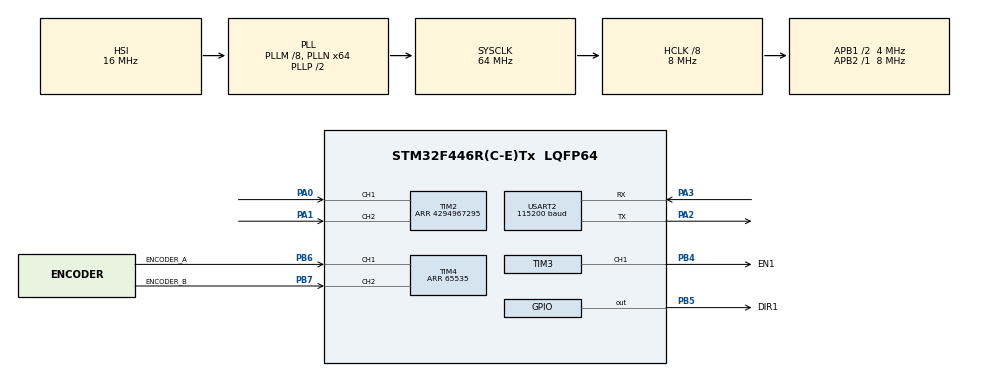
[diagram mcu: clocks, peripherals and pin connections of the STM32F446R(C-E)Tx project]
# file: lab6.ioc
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Mcu.Family=STM32F4
Mcu.Name=STM32F446R(C-E)Tx
Mcu.Package=LQFP64
NVIC.PriorityGroup=NVIC_PRIORITYGROUP_4
NVIC.TIM3_IRQn=true\:0\:0\:false\:false\:true\:true\:true\:true
NVIC.TIM7_IRQn=true\:0\:0\:false\:false\:true\:true\:true\:true
PA0-WKUP.Signal=S_TIM2_CH1_ETR
PA1.Signal=S_TIM2_CH2
PA2.Mode=Asynchronous
PA2.Signal=USART2_TX
PA3.Mode=Asynchronous
PA3.Signal=USART2_RX
PB4.GPIO_Label=EN1
PB4.Signal=S_TIM3_CH1
PB5.GPIO_Label=DIR1
PB5.Signal=GPIO_Output
PB6.GPIO_Label=ENCODER_A
PB6.Signal=S_TIM4_CH1
PB7.GPIO_Label=ENCODER_B
PB7.Signal=S_TIM4_CH2
ProjectManager.HeapSize=0x200
ProjectManager.StackSize=0x400
ProjectManager.TargetToolchain=STM32CubeIDE
RCC.AHBCLKDivider=RCC_SYSCLK_DIV8
RCC.AHBFreq_Value=8000000
RCC.APB1CLKDivider=RCC_HCLK_DIV2
RCC.APB1Freq_Value=4000000
RCC.APB1TimFreq_Value=8000000
RCC.APB2Freq_Value=8000000
RCC.APB2TimFreq_Value=8000000
RCC.CortexFreq_Value=8000000
RCC.HCLKFreq_Value=8000000
RCC.PLLM=8
RCC.PLLN=64
RCC.SYSCLKFreq_VALUE=64000000
RCC.SYSCLKSource=RCC_SYSCLKSOURCE_PLLCLK
RCC.USBFreq_Value=64000000
RCC.VCOOutputFreq_Value=128000000
SH.S_TIM2_CH1_ETR.0=TIM2_CH1,Encoder_Interface
SH.S_TIM2_CH2.0=TIM2_CH2,Encoder_Interface
SH.S_TIM3_CH1.0=TIM3_CH1,PWM Generation1 CH1
SH.S_TIM4_CH1.0=TIM4_CH1,Encoder_Interface
SH.S_TIM4_CH2.0=TIM4_CH2,Encoder_Interface
TIM2.ClockDivision=TIM_CLOCKDIVISION_DIV2
TIM2.Period=4294967295
TIM3.Channel-PWM\ Generation1\ CH1=TIM_CHANNEL_1
TIM3.Period=7
TIM3.Prescaler=499
TIM4.ClockDivision=TIM_CLOCKDIVISION_DIV2
TIM4.Period=65535
TIM7.Period=79
TIM7.Prescaler=499
USART2.BaudRate=115200
USART2.VirtualMode=VM_ASYNC
VP_TIM3_VS_ClockSourceINT.Mode=Internal
VP_TIM7_VS_ClockSourceINT.Mode=Enable_Timer
board=custom

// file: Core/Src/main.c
/* USER CODE BEGIN Header */
/**
  ******************************************************************************
  * @file           : main.c
  * @brief          : Main program body
  ******************************************************************************
  * @attention
  *
  * Copyright (c) 2024 STMicroelectronics.
  * All rights reserved.
  *
  * This software is licensed under terms that can be found in the LICENSE file
  * in the root directory of this software component.
  * If no LICENSE file comes with this software, it is provided AS-IS.
  *
  ******************************************************************************
  */
/* USER CODE END Header */
#include "main.h"

 TIM_HandleTypeDef htim2;
TIM_HandleTypeDef htim3;
TIM_HandleTypeDef htim4;
TIM_HandleTypeDef htim7;

UART_HandleTypeDef huart2;

void SystemClock_Config(void);
static void MX_GPIO_Init(void);
static void MX_TIM3_Init(void);
static void MX_USART2_UART_Init(void);
static void MX_TIM4_Init(void);
static void MX_TIM2_Init(void);
static void MX_TIM7_Init(void);

int main(void)
{

  /* MCU Configuration--------------------------------------------------------*/

  /* Reset of all peripherals, Initializes the Flash interface and the Systick. */
  HAL_Init();

  /* Configure the system clock */
  SystemClock_Config();

  /* Initialize all configured peripherals */
  MX_GPIO_Init();
  MX_TIM3_Init();
  MX_USART2_UART_Init();
  MX_TIM4_Init();
  MX_TIM2_Init();
  MX_TIM7_Init();

  /* Infinite loop */
  /* USER CODE BEGIN WHILE */
  HAL_TIM_Base_Start_IT(&htim7);
  HAL_TIM_PWM_Start_IT(&htim3, TIM_CHANNEL_1);
  HAL_TIM_Encoder_Start(&htim4, TIM_CHANNEL_ALL);
  HAL_TIM_Encoder_Start(&htim2, TIM_CHANNEL_ALL);
  while (1)
  {
    /* USER CODE END WHILE */

  }
}

void SystemClock_Config(void)
{
  RCC_OscInitTypeDef RCC_OscInitStruct = {0};
  RCC_ClkInitTypeDef RCC_ClkInitStruct = {0};

  /** Configure the main internal regulator output voltage
  */
  __HAL_RCC_PWR_CLK_ENABLE();
  __HAL_PWR_VOLTAGESCALING_CONFIG(PWR_REGULATOR_VOLTAGE_SCALE3);

  /** Initializes the RCC Oscillators according to the specified parameters
  * in the RCC_OscInitTypeDef structure.
  */
  RCC_OscInitStruct.OscillatorType = RCC_OSCILLATORTYPE_HSI;
  RCC_OscInitStruct.HSIState = RCC_HSI_ON;
  RCC_OscInitStruct.HSICalibrationValue = RCC_HSICALIBRATION_DEFAULT;
  RCC_OscInitStruct.PLL.PLLState = RCC_PLL_ON;
  RCC_OscInitStruct.PLL.PLLSource = RCC_PLLSOURCE_HSI;
  RCC_OscInitStruct.PLL.PLLM = 8;
  RCC_OscInitStruct.PLL.PLLN = 64;
  RCC_OscInitStruct.PLL.PLLP = RCC_PLLP_DIV2;
  RCC_OscInitStruct.PLL.PLLQ = 2;
  RCC_OscInitStruct.PLL.PLLR = 2;
  if (HAL_RCC_OscConfig(&RCC_OscInitStruct) != HAL_OK)
  {
    Error_Handler();
  }

  /** Initializes the CPU, AHB and APB buses clocks
  */
  RCC_ClkInitStruct.ClockType = RCC_CLOCKTYPE_HCLK|RCC_CLOCKTYPE_SYSCLK
                              |RCC_CLOCKTYPE_PCLK1|RCC_CLOCKTYPE_PCLK2;
  RCC_ClkInitStruct.SYSCLKSource = RCC_SYSCLKSOURCE_PLLCLK;
  RCC_ClkInitStruct.AHBCLKDivider = RCC_SYSCLK_DIV8;
  RCC_ClkInitStruct.APB1CLKDivider = RCC_HCLK_DIV2;
  RCC_ClkInitStruct.APB2CLKDivider = RCC_HCLK_DIV1;

  if (HAL_RCC_ClockConfig(&RCC_ClkInitStruct, FLASH_LATENCY_0) != HAL_OK)
  {
    Error_Handler();
  }
}

static void MX_TIM2_Init(void)
{

  TIM_Encoder_InitTypeDef sConfig = {0};
  TIM_MasterConfigTypeDef sMasterConfig = {0};

  htim2.Instance = TIM2;
  htim2.Init.Prescaler = 0;
  htim2.Init.CounterMode = TIM_COUNTERMODE_UP;
  htim2.Init.Period = 4294967295;
  htim2.Init.ClockDivision = TIM_CLOCKDIVISION_DIV2;
  htim2.Init.AutoReloadPreload = TIM_AUTORELOAD_PRELOAD_DISABLE;
  sConfig.EncoderMode = TIM_ENCODERMODE_TI1;
  sConfig.IC1Polarity = TIM_ICPOLARITY_RISING;
  sConfig.IC1Selection = TIM_ICSELECTION_DIRECTTI;
  sConfig.IC1Prescaler = TIM_ICPSC_DIV1;
  sConfig.IC1Filter = 0;
  sConfig.IC2Polarity = TIM_ICPOLARITY_RISING;
  sConfig.IC2Selection = TIM_ICSELECTION_DIRECTTI;
  sConfig.IC2Prescaler = TIM_ICPSC_DIV1;
  sConfig.IC2Filter = 0;
  if (HAL_TIM_Encoder_Init(&htim2, &sConfig) != HAL_OK)
  {
    Error_Handler();
  }
  sMasterConfig.MasterOutputTrigger = TIM_TRGO_RESET;
  sMasterConfig.MasterSlaveMode = TIM_MASTERSLAVEMODE_DISABLE;
  if (HAL_TIMEx_MasterConfigSynchronization(&htim2, &sMasterConfig) != HAL_OK)
  {
    Error_Handler();
  }

}

static void MX_TIM3_Init(void)
{

  TIM_ClockConfigTypeDef sClockSourceConfig = {0};
  TIM_MasterConfigTypeDef sMasterConfig = {0};
  TIM_OC_InitTypeDef sConfigOC = {0};

  htim3.Instance = TIM3;
  htim3.Init.Prescaler = 499;
  htim3.Init.CounterMode = TIM_COUNTERMODE_UP;
  htim3.Init.Period = 7;
  htim3.Init.ClockDivision = TIM_CLOCKDIVISION_DIV1;
  htim3.Init.AutoReloadPreload = TIM_AUTORELOAD_PRELOAD_DISABLE;
  if (HAL_TIM_Base_Init(&htim3) != HAL_OK)
  {
    Error_Handler();
  }
  sClockSourceConfig.ClockSource = TIM_CLOCKSOURCE_INTERNAL;
  if (HAL_TIM_ConfigClockSource(&htim3, &sClockSourceConfig) != HAL_OK)
  {
    Error_Handler();
  }
  if (HAL_TIM_PWM_Init(&htim3) != HAL_OK)
  {
    Error_Handler();
  }
  sMasterConfig.MasterOutputTrigger = TIM_TRGO_RESET;
  sMasterConfig.MasterSlaveMode = TIM_MASTERSLAVEMODE_DISABLE;
  if (HAL_TIMEx_MasterConfigSynchronization(&htim3, &sMasterConfig) != HAL_OK)
  {
    Error_Handler();
  }
  sConfigOC.OCMode = TIM_OCMODE_PWM1;
  sConfigOC.Pulse = 0;
  sConfigOC.OCPolarity = TIM_OCPOLARITY_HIGH;
  sConfigOC.OCFastMode = TIM_OCFAST_DISABLE;
  if (HAL_TIM_PWM_ConfigChannel(&htim3, &sConfigOC, TIM_CHANNEL_1) != HAL_OK)
  {
    Error_Handler();
  }
  HAL_TIM_MspPostInit(&htim3);

}

static void MX_TIM4_Init(void)
{

  TIM_Encoder_InitTypeDef sConfig = {0};
  TIM_MasterConfigTypeDef sMasterConfig = {0};

  htim4.Instance = TIM4;
  htim4.Init.Prescaler = 0;
  htim4.Init.CounterMode = TIM_COUNTERMODE_UP;
  htim4.Init.Period = 65535;
  htim4.Init.ClockDivision = TIM_CLOCKDIVISION_DIV2;
  htim4.Init.AutoReloadPreload = TIM_AUTORELOAD_PRELOAD_DISABLE;
  sConfig.EncoderMode = TIM_ENCODERMODE_TI1;
  sConfig.IC1Polarity = TIM_ICPOLARITY_RISING;
  sConfig.IC1Selection = TIM_ICSELECTION_DIRECTTI;
  sConfig.IC1Prescaler = TIM_ICPSC_DIV1;
  sConfig.IC1Filter = 0;
  sConfig.IC2Polarity = TIM_ICPOLARITY_RISING;
  sConfig.IC2Selection = TIM_ICSELECTION_DIRECTTI;
  sConfig.IC2Prescaler = TIM_ICPSC_DIV1;
  sConfig.IC2Filter = 0;
  if (HAL_TIM_Encoder_Init(&htim4, &sConfig) != HAL_OK)
  {
    Error_Handler();
  }
  sMasterConfig.MasterOutputTrigger = TIM_TRGO_RESET;
  sMasterConfig.MasterSlaveMode = TIM_MASTERSLAVEMODE_DISABLE;
  if (HAL_TIMEx_MasterConfigSynchronization(&htim4, &sMasterConfig) != HAL_OK)
  {
    Error_Handler();
  }

}

static void MX_TIM7_Init(void)
{

  TIM_MasterConfigTypeDef sMasterConfig = {0};

  htim7.Instance = TIM7;
  htim7.Init.Prescaler = 499;
  htim7.Init.CounterMode = TIM_COUNTERMODE_UP;
  htim7.Init.Period = 79;
  htim7.Init.AutoReloadPreload = TIM_AUTORELOAD_PRELOAD_DISABLE;
  if (HAL_TIM_Base_Init(&htim7) != HAL_OK)
  {
    Error_Handler();
  }
  sMasterConfig.MasterOutputTrigger = TIM_TRGO_RESET;
  sMasterConfig.MasterSlaveMode = TIM_MASTERSLAVEMODE_DISABLE;
  if (HAL_TIMEx_MasterConfigSynchronization(&htim7, &sMasterConfig) != HAL_OK)
  {
    Error_Handler();
  }

}

static void MX_USART2_UART_Init(void)
{

  huart2.Instance = USART2;
  huart2.Init.BaudRate = 115200;
  huart2.Init.WordLength = UART_WORDLENGTH_8B;
  huart2.Init.StopBits = UART_STOPBITS_1;
  huart2.Init.Parity = UART_PARITY_NONE;
  huart2.Init.Mode = UART_MODE_TX_RX;
  huart2.Init.HwFlowCtl = UART_HWCONTROL_NONE;
  huart2.Init.OverSampling = UART_OVERSAMPLING_16;
  if (HAL_UART_Init(&huart2) != HAL_OK)
  {
    Error_Handler();
  }

}

static void MX_GPIO_Init(void)
{
  GPIO_InitTypeDef GPIO_InitStruct = {0};

  /* GPIO Ports Clock Enable */
  __HAL_RCC_GPIOA_CLK_ENABLE();
  __HAL_RCC_GPIOB_CLK_ENABLE();

  /*Configure GPIO pin Output Level */
  HAL_GPIO_WritePin(DIR1_GPIO_Port, DIR1_Pin, GPIO_PIN_RESET);

  /*Configure GPIO pin : DIR1_Pin */
  GPIO_InitStruct.Pin = DIR1_Pin;
  GPIO_InitStruct.Mode = GPIO_MODE_OUTPUT_PP;
  GPIO_InitStruct.Pull = GPIO_NOPULL;
  GPIO_InitStruct.Speed = GPIO_SPEED_FREQ_LOW;
  HAL_GPIO_Init(DIR1_GPIO_Port, &GPIO_InitStruct);

}

void Error_Handler(void)
{
  __disable_irq();
  while (1)
  {
  }
}
